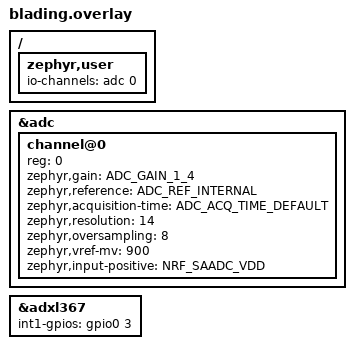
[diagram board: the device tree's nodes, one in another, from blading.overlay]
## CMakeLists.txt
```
# SPDX-License-Identifier: Apache-2.0
cmake_minimum_required(VERSION 3.20.0)

# App devicetree additions (ADC, ADXL367 INT1). The board overlay in boards/
# (flash layout) is still picked up automatically.
list(APPEND EXTRA_DTC_OVERLAY_FILE ${CMAKE_CURRENT_LIST_DIR}/blading.overlay)

find_package(Zephyr REQUIRED HINTS $ENV{ZEPHYR_BASE})
project(blading_tag)

target_sources(app PRIVATE
  src/main.c
  src/app.c
  src/ble.c
  src/proto.c
  src/samplebuf.c
  src/imu.c
  src/motion.c
  src/battery.c
  src/led.c
)
target_sources_ifdef(CONFIG_BLADING_TEST_HOOKS app PRIVATE src/testhook.c)
```

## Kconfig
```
mainmenu "blading-tag"

menu "blading-tag"

config BLADING_BUFFER_SAMPLES
	int "Samples buffered on the tag"
	default 14336
	help
	  Samples the tag can hold while the link is down or too slow
	  (reported as buffer_capacity in Info). 12 bytes each; 14336 is
	  72 s at 200 Hz and takes 168 KB of the 256 KB RAM.

config BLADING_LINK_LOSS_STOP_S
	int "Stop recording after this long without a connection (s)"
	default 300

config BLADING_IDLE_SLEEP_S
	int "Go to System OFF after this long idle (s), 0 = never"
	default 600
	help
	  Idle means READY, not connected and no motion. Only applies when the
	  ADXL367 works and can be armed as a wake-up source, since motion is
	  what wakes the tag again.

config BLADING_MOTION_THRESHOLD_MG
	int "Wake-on-motion threshold (mg)"
	default 150
	range 10 2000

config BLADING_LOW_BATTERY_MV
	int "Status LOW_BATTERY below this voltage (mV)"
	default 2500

config BLADING_TEST_HOOKS
	bool "Hooks for the hardware tests (test builds only)"
	help
	  A RAM mailbox that a J-Link writes commands into, e.g. "short
	  button press", for host/tests/hw. Polls every 20 ms, so it costs
	  power: only for test builds (make build-test, test.conf).

endmenu

source "Kconfig.zephyr"
```

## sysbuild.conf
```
# MCUboot + app. The factory bootloader on the Tag is MCUboot in
# swap-using-move mode with NCS's default nRF54L15 layout (MCUboot 62 KiB,
# slot0 at 0x10000), so we build the same thing.
SB_CONFIG_BOOTLOADER_MCUBOOT=y
SB_CONFIG_MCUBOOT_MODE_SWAP_USING_MOVE=y
```

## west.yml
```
# West manifest for the blading-tag firmware.
#
# The workspace topdir is the repo root (`west init -l firmware`), so
# zephyr/, nrf/, modules/, bootloader/, ... are cloned next to firmware/ and
# are gitignored. See firmware/README.md.
manifest:
  remotes:
    - name: ncs
      url-base: https://github.com/nrfconnect
  projects:
    - name: nrf
      remote: ncs
      repo-path: sdk-nrf
      revision: v3.4.0
      import: true
  self:
    path: firmware
```

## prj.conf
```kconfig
# --- Bluetooth -------------------------------------------------------------
CONFIG_BT=y
CONFIG_BT_PERIPHERAL=y
CONFIG_BT_MAX_CONN=1
CONFIG_BT_DEVICE_NAME="BladeTag"
CONFIG_BT_DEVICE_NAME_DYNAMIC=y
CONFIG_BT_DEVICE_NAME_MAX=16

CONFIG_BT_DIS=y
CONFIG_BT_DIS_MODEL_NUMBER_STR="nRF54L15 Tag"
CONFIG_BT_DIS_FW_REV=y

# ATT MTU 247 and full-size LL packets: one Data notification = 19 samples.
CONFIG_BT_L2CAP_TX_MTU=247
CONFIG_BT_BUF_ACL_TX_SIZE=251
CONFIG_BT_BUF_ACL_RX_SIZE=251
CONFIG_BT_CTLR_DATA_LENGTH_MAX=251

# Connection parameters from PROTOCOL.md 1.2: 30-50 ms, latency 0, 4 s
# supervision timeout, 2M PHY.
CONFIG_BT_GAP_AUTO_UPDATE_CONN_PARAMS=y
CONFIG_BT_PERIPHERAL_PREF_MIN_INT=24
CONFIG_BT_PERIPHERAL_PREF_MAX_INT=40
CONFIG_BT_PERIPHERAL_PREF_LATENCY=0
CONFIG_BT_PERIPHERAL_PREF_TIMEOUT=400
CONFIG_BT_AUTO_PHY_PERIPHERAL_2M=y
# Highest TX power the tag's QFN48 nRF54L15 supports (+8 dBm is CSP only).
# Costs ~+60 uA while recording and ~+5 uA while advertising in READY; worth
# it for an ankle tag talking to a phone on the body. See PLAN.md.
CONFIG_BT_CTLR_TX_PWR_PLUS_7=y

# Control writes run in the BT RX thread and save settings / talk to the IMU.
CONFIG_BT_RX_STACK_SIZE=3072

# --- Firmware updates over BLE (MCUboot + mcumgr SMP) -----------------------
CONFIG_NCS_SAMPLE_MCUMGR_BT_OTA_DFU=y
# A crash resets instead of halting, so MCUboot can revert an unconfirmed image.
CONFIG_RESET_ON_FATAL_ERROR=y

# --- Sensors ---------------------------------------------------------------
CONFIG_GPIO=y
CONFIG_SPI=y
CONFIG_I2C=y
CONFIG_SENSOR=y
# The BMI270 driver does the chip init; src/imu.c runs the FIFO itself.
CONFIG_BMI270=y
CONFIG_BMI270_TRIGGER_NONE=y
# src/motion.c drives the ADXL367 directly. BME688 is unused.
CONFIG_ADXL367=n
CONFIG_BME680=n
CONFIG_ADC=y

# --- Persistence (session_id, position) -------------------------------------
CONFIG_FLASH=y
CONFIG_FLASH_MAP=y
CONFIG_ZMS=y
CONFIG_SETTINGS=y
CONFIG_SETTINGS_ZMS=y

# --- Power -------------------------------------------------------------------
CONFIG_POWEROFF=y

CONFIG_SYSTEM_WORKQUEUE_STACK_SIZE=3072

# Logging over RTT (J-Link). The Tag has no UART connector.
CONFIG_LOG=y
CONFIG_USE_SEGGER_RTT=y
CONFIG_LOG_BACKEND_RTT=y
CONFIG_LOG_BACKEND_UART=n
CONFIG_UART_CONSOLE=n
CONFIG_RTT_CONSOLE=y
# MCUboot's boot log alone nearly fills the default 1 KB.
CONFIG_SEGGER_RTT_BUFFER_SIZE_UP=4096
```

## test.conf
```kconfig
# Test build for the hardware tests in host/tests/hw (make build-test).
# Applied on top of prj.conf. Don't ship it: it polls a RAM mailbox.
CONFIG_BLADING_TEST_HOOKS=y
# The tag sits still in the DK header between test runs, and the J-Link can't
# wake it from System OFF.
CONFIG_BLADING_IDLE_SLEEP_S=0
```

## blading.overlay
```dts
/*
 * App devicetree additions, on top of boards/nrf54l15tag_nrf54l15_cpuapp.overlay
 * (the flash layout, owned by the OTA setup). Added via EXTRA_DTC_OVERLAY_FILE.
 */
#include <zephyr/dt-bindings/adc/adc.h>
#include <zephyr/dt-bindings/adc/nrf-saadc.h>

/ {
	zephyr,user {
		io-channels = <&adc 0>;
	};
};

/* Coin-cell voltage: VDD, gain 1/4 against the 0.9 V reference = 3.6 V full scale. */
&adc {
	#address-cells = <1>;
	#size-cells = <0>;
	status = "okay";

	channel@0 {
		reg = <0>;
		zephyr,gain = "ADC_GAIN_1_4";
		zephyr,reference = "ADC_REF_INTERNAL";
		zephyr,acquisition-time = <ADC_ACQ_TIME_DEFAULT>;
		zephyr,resolution = <14>;
		zephyr,oversampling = <8>;
		zephyr,vref-mv = <900>;
		zephyr,input-positive = <NRF_SAADC_VDD>;
	};
};

/*
 * ADXL367 INT1 is on P0.03 (as in sdk-nrf's fast_pair/locator_tag overlay for
 * this board). Port 0 supports SENSE, so it can wake from System OFF.
 */
&adxl367 {
	int1-gpios = <&gpio0 3 GPIO_ACTIVE_HIGH>;
};
```

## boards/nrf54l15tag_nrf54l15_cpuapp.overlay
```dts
/*
 * Flash layout of the factory-programmed nRF54L15 Tag.
 *
 * The factory MCUboot uses NCS's "FLPR" partition variant
 * (WITH_FLPR_PARTITIONS in nrf54l15_cpuapp_partition.dtsi), not the default
 * one. Read back from a stock tag over SWD:
 *
 *   mcuboot  0x000000  62 KiB
 *   slot0    0x010000  664 KiB  (image trailer at the end, 0x0b6000)
 *   slot1    0x0b6000  664 KiB
 *   storage  0x15c000  36 KiB
 *
 * The app has to agree with the bootloader on these, or it writes its
 * "confirmed" flag to the wrong place and MCUboot reverts the update. Keep
 * this in sync with sysbuild/mcuboot.overlay (which includes this file).
 */

/delete-node/ &slot1_partition;
/delete-node/ &storage_partition;

&cpuapp_rram {
	partitions {
		slot0_partition: partition@10000 {
			compatible = "zephyr,mapped-partition";
			label = "image-0";
			reg = <0x10000 DT_SIZE_K(664)>;
		};

		slot1_partition: partition@b6000 {
			compatible = "zephyr,mapped-partition";
			label = "image-1";
			reg = <0xb6000 DT_SIZE_K(664)>;
		};

		storage_partition: partition@15c000 {
			compatible = "zephyr,mapped-partition";
			label = "storage";
			reg = <0x15c000 DT_SIZE_K(36)>;
		};
	};
};
```

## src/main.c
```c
/*
 * blading-tag firmware for the nRF54L15 Tag.
 *
 * Streams BMI270 accelerometer + gyroscope data over BLE when the app asks
 * for it (PROTOCOL.md), sleeps in System OFF when idle, and takes firmware
 * updates over BLE (MCUboot + mcumgr SMP). See app.c for the state machine.
 */
#include <app_version.h>
#include <zephyr/bluetooth/bluetooth.h>
#include <zephyr/dfu/mcuboot.h>
#include <zephyr/kernel.h>
#include <zephyr/logging/log.h>

#include "app.h"
#include "ble.h"

LOG_MODULE_REGISTER(main, LOG_LEVEL_INF);

int main(void)
{
	int err;

	LOG_INF("blading-tag %s", APP_VERSION_EXTENDED_STRING);

	app_init();

	err = bt_enable(NULL);
	if (err) {
		LOG_ERR("bt_enable failed: %d", err);
		return 0;
	}

	ble_init();

	/*
	 * Bluetooth (and with it SMP) is up, so a further update is possible:
	 * keep this image. If we never get here, MCUboot reverts it on reset.
	 */
	if (!boot_is_img_confirmed()) {
		err = boot_write_img_confirmed();
		LOG_INF("image confirmed: %d", err);
	}

	app_run();
	return 0;
}
```

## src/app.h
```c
/*
 * Tag state machine (PROTOCOL.md 1.4-1.9): READY / RECORDING, the sample
 * buffer and Data packets, link loss, persistence, button, sleep.
 */
#ifndef BLADING_APP_H_
#define BLADING_APP_H_

#include <stdbool.h>
#include <stddef.h>
#include <stdint.h>

#include "proto.h"

/* Before bt_enable(): settings, LED, sensors, button. */
int app_init(void);
/* After Bluetooth is up: periodic work, advertising. */
void app_run(void);

/* Called by ble.c. */
void app_encode_info(uint8_t out[PROTO_INFO_LEN]);
void app_encode_status(uint8_t out[PROTO_STATUS_LEN]);
/* Returns 0 or a PROTO_ERR_* code. */
int app_control(const uint8_t *buf, size_t len);
void app_on_connected(void);
void app_on_disconnected(void);
/* The peer acknowledged the Data packet sent with this token. */
void app_on_data_acked(uint32_t token);
/* Wake the TX thread (new data, notifications enabled, TX done). */
void app_kick(void);
void app_adv_fields(uint8_t *state, uint8_t *position, uint16_t *battery_mv, bool *fast);

/* What a short button press does: start (defaults) while idle, otherwise ignore. Also
 * used by testhook.c. Call from the system workqueue. */
void app_button_short(void);
/* Release after a press begun in was_recording; held means the 2 s threshold passed. */
void app_button_release(bool was_recording, bool held);

#endif /* BLADING_APP_H_ */
```

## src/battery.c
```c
/*
 * Coin-cell voltage. The Tag runs straight off the CR2032, so VDD is the
 * battery voltage. Measured with the SAADC's internal VDD input (see
 * blading.overlay: gain 1/4, 0.9 V reference, so 3.6 V full scale).
 */
#include "battery.h"

#include <zephyr/drivers/adc.h>
#include <zephyr/kernel.h>
#include <zephyr/logging/log.h>

LOG_MODULE_REGISTER(battery, LOG_LEVEL_INF);

static const struct adc_dt_spec vdd = ADC_DT_SPEC_GET(DT_PATH(zephyr_user));
static atomic_t last_mv;
static bool ready;

int battery_init(void)
{
	if (!adc_is_ready_dt(&vdd)) {
		return -ENODEV;
	}
	int err = adc_channel_setup_dt(&vdd);

	if (err) {
		LOG_ERR("ADC setup failed: %d", err);
		return err;
	}
	ready = true;
	return battery_measure();
}

int battery_measure(void)
{
	int16_t raw;
	struct adc_sequence seq = {
		.buffer = &raw,
		.buffer_size = sizeof(raw),
	};
	int32_t mv;
	int err;

	if (!ready) {
		return -ENODEV;
	}

	adc_sequence_init_dt(&vdd, &seq);
	err = adc_read_dt(&vdd, &seq);
	if (err) {
		return err;
	}

	mv = raw;
	err = adc_raw_to_millivolts_dt(&vdd, &mv);
	if (err) {
		return err;
	}

	atomic_set(&last_mv, CLAMP(mv, 0, UINT16_MAX));
	return 0;
}

uint16_t battery_mv(void)
{
	return (uint16_t)atomic_get(&last_mv);
}
```

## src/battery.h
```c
#ifndef BLADING_BATTERY_H_
#define BLADING_BATTERY_H_

#include <stdint.h>

int battery_init(void);
/* Take a new reading. */
int battery_measure(void);
/* Last reading in mV, 0 if none. */
uint16_t battery_mv(void);

#endif /* BLADING_BATTERY_H_ */
```

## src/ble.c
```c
#include "ble.h"

#include <stdio.h>
#include <string.h>
#include <zephyr/bluetooth/bluetooth.h>
#include <zephyr/bluetooth/conn.h>
#include <zephyr/bluetooth/gatt.h>
#include <zephyr/bluetooth/hci.h>
#include <zephyr/bluetooth/uuid.h>
#include <zephyr/logging/log.h>

#include "app.h"
#include "proto.h"

LOG_MODULE_REGISTER(ble, LOG_LEVEL_INF);

#define BLADING_UUID(short16)                                                                      \
	BT_UUID_128_ENCODE(PROTO_UUID_W32(short16), PROTO_UUID_W1, PROTO_UUID_W2, PROTO_UUID_W3,   \
			   PROTO_UUID_W48)

static const struct bt_uuid_128 svc_uuid = BT_UUID_INIT_128(BLADING_UUID(0x0001));
static const struct bt_uuid_128 info_uuid = BT_UUID_INIT_128(BLADING_UUID(0x0002));
static const struct bt_uuid_128 control_uuid = BT_UUID_INIT_128(BLADING_UUID(0x0003));
static const struct bt_uuid_128 status_uuid = BT_UUID_INIT_128(BLADING_UUID(0x0004));
static const struct bt_uuid_128 data_uuid = BT_UUID_INIT_128(BLADING_UUID(0x0005));

/* Notifications in flight at once; matches CONFIG_BT_CONN_TX_MAX. */
#define TX_CREDITS 3

static K_SEM_DEFINE(tx_credits, 0, TX_CREDITS);
static struct k_spinlock conn_lock;
static struct bt_conn *cur_conn;
/* Bumped on every connect/disconnect, so stale completions are ignored. */
static atomic_t conn_gen;
static atomic_t shutting_down;

static char name[sizeof("BladeTag-XXXX")];
static uint8_t mfg[PROTO_ADV_MFG_LEN];

static ssize_t read_info(struct bt_conn *conn, const struct bt_gatt_attr *attr, void *buf,
			 uint16_t len, uint16_t offset)
{
	uint8_t v[PROTO_INFO_LEN];

	app_encode_info(v);
	return bt_gatt_attr_read(conn, attr, buf, len, offset, v, sizeof(v));
}

static ssize_t read_status(struct bt_conn *conn, const struct bt_gatt_attr *attr, void *buf,
			   uint16_t len, uint16_t offset)
{
	uint8_t v[PROTO_STATUS_LEN];

	app_encode_status(v);
	return bt_gatt_attr_read(conn, attr, buf, len, offset, v, sizeof(v));
}

static ssize_t write_control(struct bt_conn *conn, const struct bt_gatt_attr *attr,
			     const void *buf, uint16_t len, uint16_t offset, uint8_t flags)
{
	if (offset != 0) {
		return BT_GATT_ERR(BT_ATT_ERR_INVALID_OFFSET);
	}

	int err = app_control(buf, len);

	return err ? BT_GATT_ERR(err) : len;
}

static void ccc_changed(const struct bt_gatt_attr *attr, uint16_t value)
{
	app_kick();
}

BT_GATT_SERVICE_DEFINE(blading_svc,
	BT_GATT_PRIMARY_SERVICE(&svc_uuid),
	BT_GATT_CHARACTERISTIC(&info_uuid.uuid, BT_GATT_CHRC_READ, BT_GATT_PERM_READ, read_info,
			       NULL, NULL),
	BT_GATT_CHARACTERISTIC(&control_uuid.uuid, BT_GATT_CHRC_WRITE, BT_GATT_PERM_WRITE, NULL,
			       write_control, NULL),
	BT_GATT_CHARACTERISTIC(&status_uuid.uuid, BT_GATT_CHRC_READ | BT_GATT_CHRC_NOTIFY,
			       BT_GATT_PERM_READ, read_status, NULL, NULL),
	BT_GATT_CCC(ccc_changed, BT_GATT_PERM_READ | BT_GATT_PERM_WRITE),
	BT_GATT_CHARACTERISTIC(&data_uuid.uuid, BT_GATT_CHRC_NOTIFY, BT_GATT_PERM_NONE, NULL, NULL,
			       NULL),
	BT_GATT_CCC(ccc_changed, BT_GATT_PERM_READ | BT_GATT_PERM_WRITE),
);

/* Value attributes, see the attribute list above. */
#define STATUS_ATTR (&blading_svc.attrs[6])
#define DATA_ATTR   (&blading_svc.attrs[9])

static struct bt_conn *conn_get(void)
{
	k_spinlock_key_t key = k_spin_lock(&conn_lock);
	struct bt_conn *conn = cur_conn ? bt_conn_ref(cur_conn) : NULL;

	k_spin_unlock(&conn_lock, key);
	return conn;
}

bool ble_connected(void)
{
	struct bt_conn *conn = conn_get();

	if (conn) {
		bt_conn_unref(conn);
	}
	return conn != NULL;
}

uint16_t ble_mtu(void)
{
	struct bt_conn *conn = conn_get();
	uint16_t mtu = 0;

	if (conn) {
		mtu = bt_gatt_get_mtu(conn);
		bt_conn_unref(conn);
	}
	return mtu;
}

bool ble_data_subscribed(void)
{
	struct bt_conn *conn = conn_get();
	bool on = false;

	if (conn) {
		on = bt_gatt_is_subscribed(conn, DATA_ATTR, BT_GATT_CCC_NOTIFY);
		bt_conn_unref(conn);
	}
	return on;
}

/*
 * A notification's user_data: the connection generation it was sent on
 * (low 8 bits) and, for Data, the caller's token (upper 24 bits).
 */
#define UD_MAKE(gen, token) ((void *)(uintptr_t)(((uint32_t)(token) << 8) | ((gen) & 0xff)))
#define UD_GEN(ud)          ((uint32_t)(uintptr_t)(ud) & 0xff)
#define UD_TOKEN(ud)        ((uint32_t)(uintptr_t)(ud) >> 8)

static bool same_conn_gen(void *user_data)
{
	return UD_GEN(user_data) == ((uint32_t)atomic_get(&conn_gen) & 0xff);
}

static void notify_done(struct bt_conn *conn, void *user_data)
{
	if (same_conn_gen(user_data)) {
		k_sem_give(&tx_credits);
	}
	app_kick();
}

/*
 * Zephyr calls this once the controller reports the packet complete:
 * acknowledged by the peer's link layer, or flushed at a link loss (app.c
 * keeps a few packets for that). It also calls it for packets the host
 * throws away at a disconnect: process_unack_tx() destroys them after the
 * connection is already in DISCONNECT_COMPLETE, and ATT runs the callback
 * from a work item that can come before our disconnected() callback. So only
 * a callback while still connected, on the same connection, is passed on.
 * Getting it wrong the other way only sends a packet twice.
 */
static void data_done(struct bt_conn *conn, void *user_data)
{
	struct bt_conn_info info;
	bool acked = same_conn_gen(user_data) && bt_conn_get_info(conn, &info) == 0 &&
		     info.state == BT_CONN_STATE_CONNECTED;

	if (same_conn_gen(user_data)) {
		k_sem_give(&tx_credits);
	}
	if (acked) {
		app_on_data_acked(UD_TOKEN(user_data));
	}
	app_kick();
}

static int notify(const struct bt_gatt_attr *attr, const uint8_t *buf, size_t len,
		  k_timeout_t timeout, bt_gatt_complete_func_t done, uint32_t token)
{
	struct bt_conn *conn = conn_get();
	int err;

	if (!conn) {
		return -ENOTCONN;
	}
	if (!bt_gatt_is_subscribed(conn, attr, BT_GATT_CCC_NOTIFY)) {
		bt_conn_unref(conn);
		return -EACCES;
	}

	uint32_t gen = (uint32_t)atomic_get(&conn_gen);

	if (k_sem_take(&tx_credits, timeout) != 0) {
		bt_conn_unref(conn);
		return -EAGAIN;
	}

	struct bt_gatt_notify_params params = {
		.attr = attr,
		.data = buf,
		.len = len,
		.func = done,
		.user_data = UD_MAKE(gen, token),
	};

	err = bt_gatt_notify_cb(conn, &params);
	if (err) {
		k_sem_give(&tx_credits);
		err = err == -ENOTCONN ? -ENOTCONN : -EAGAIN;
	}
	bt_conn_unref(conn);
	return err;
}

int ble_notify_status(const uint8_t *buf, size_t len, k_timeout_t timeout)
{
	return notify(STATUS_ATTR, buf, len, timeout, notify_done, 0);
}

int ble_notify_data(const uint8_t *buf, size_t len, k_timeout_t timeout, uint32_t token)
{
	return notify(DATA_ATTR, buf, len, timeout, data_done, token);
}

/* --- Advertising ---------------------------------------------------------- */

static struct bt_data ad[] = {
	BT_DATA_BYTES(BT_DATA_FLAGS, BT_LE_AD_GENERAL | BT_LE_AD_NO_BREDR),
	BT_DATA_BYTES(BT_DATA_UUID128_ALL, BLADING_UUID(0x0001)),
	BT_DATA(BT_DATA_MANUFACTURER_DATA, mfg, sizeof(mfg)),
};

static struct bt_data sd[] = {
	BT_DATA(BT_DATA_NAME_COMPLETE, name, 0),
};

/*
 * ~1 s when idle. While recording without a link, advertise faster so the
 * phone reconnects before the buffer fills.
 */
static const struct bt_le_adv_param adv_slow =
	BT_LE_ADV_PARAM_INIT(BT_LE_ADV_OPT_CONN, 1600, 1760, NULL); /* 1.0-1.1 s */
static const struct bt_le_adv_param adv_fast =
	BT_LE_ADV_PARAM_INIT(BT_LE_ADV_OPT_CONN, 160, 240, NULL); /* 100-150 ms */

/* Whether we started advertising, and with which interval. Cleared on connect. */
static atomic_t adv_on;
static bool adv_on_fast;

/*
 * Runs on the system workqueue only. Stopping connectable advertising frees
 * its pending connection object, which calls recycled() -> ble_adv_refresh()
 * again. So only stop when the interval changes; otherwise update the data in
 * place, or this loops forever.
 */
static void adv_work_fn(struct k_work *work)
{
	uint8_t state, position;
	uint16_t battery;
	bool fast;
	int err;

	if (atomic_get(&shutting_down) || ble_connected()) {
		return;
	}

	app_adv_fields(&state, &position, &battery, &fast);
	proto_encode_adv_mfg(mfg, state, position, battery);

	if (atomic_get(&adv_on)) {
		if (fast == adv_on_fast &&
		    bt_le_adv_update_data(ad, ARRAY_SIZE(ad), sd, ARRAY_SIZE(sd)) == 0) {
			return;
		}
		bt_le_adv_stop();
		atomic_set(&adv_on, 0);
	}

	err = bt_le_adv_start(fast ? &adv_fast : &adv_slow, ad, ARRAY_SIZE(ad), sd,
			      ARRAY_SIZE(sd));
	if (err == 0) {
		atomic_set(&adv_on, 1);
		adv_on_fast = fast;
		LOG_INF("advertising (%s)", fast ? "fast" : "slow");
	} else if (err == -ENOMEM) {
		/* The old connection object isn't recycled yet; recycled() retries. */
		LOG_DBG("adv start: %d", err);
	} else {
		LOG_WRN("adv start failed: %d", err);
	}
}

static K_WORK_DEFINE(adv_work, adv_work_fn);

void ble_adv_refresh(void)
{
	k_work_submit(&adv_work);
}

/* --- Connections ------------------------------------------------------------ */

static void reset_credits(void)
{
	atomic_inc(&conn_gen);
	k_sem_reset(&tx_credits);
	for (int i = 0; i < TX_CREDITS; i++) {
		k_sem_give(&tx_credits);
	}
}

static void connected(struct bt_conn *conn, uint8_t err)
{
	if (err) {
		LOG_WRN("connection failed: 0x%02x", err);
		return;
	}

	k_spinlock_key_t key = k_spin_lock(&conn_lock);

	if (cur_conn) {
		k_spin_unlock(&conn_lock, key);
		return;
	}
	cur_conn = bt_conn_ref(conn);
	k_spin_unlock(&conn_lock, key);

	/* The controller stops advertising when a connection is made. */
	atomic_set(&adv_on, 0);
	reset_credits();
	LOG_INF("connected");
	app_on_connected();
}

static void disconnected(struct bt_conn *conn, uint8_t reason)
{
	k_spinlock_key_t key = k_spin_lock(&conn_lock);

	if (conn != cur_conn) {
		k_spin_unlock(&conn_lock, key);
		return;
	}
	cur_conn = NULL;
	k_spin_unlock(&conn_lock, key);
	bt_conn_unref(conn);

	reset_credits();
	LOG_INF("disconnected (0x%02x)", reason);
	app_on_disconnected();
}

/* The connection object is free again: advertising can restart. */
static void recycled(void)
{
	ble_adv_refresh();
}

BT_CONN_CB_DEFINE(conn_cb) = {
	.connected = connected,
	.disconnected = disconnected,
	.recycled = recycled,
};

int ble_init(void)
{
	bt_addr_le_t addrs[1];
	size_t count = 1;

	bt_id_get(addrs, &count);
	snprintf(name, sizeof(name), "BladeTag-%02X%02X", addrs[0].a.val[1], addrs[0].a.val[0]);
	sd[0].data_len = strlen(name);
	bt_set_name(name);

	reset_credits();
	ble_adv_refresh();
	LOG_INF("name %s", name);
	return 0;
}

void ble_shutdown(void)
{
	atomic_set(&shutting_down, 1);

	struct bt_conn *conn = conn_get();

	if (conn) {
		bt_conn_disconnect(conn, BT_HCI_ERR_REMOTE_USER_TERM_CONN);
		bt_conn_unref(conn);
		for (int i = 0; i < 20 && ble_connected(); i++) {
			k_msleep(50);
		}
	}
	bt_le_adv_stop();
	atomic_set(&adv_on, 0);
}
```

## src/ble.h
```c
/*
 * Bluetooth side of the protocol: advertising, the Blading GATT service and
 * notification flow control. The protocol state lives in app.c.
 */
#ifndef BLADING_BLE_H_
#define BLADING_BLE_H_

#include <stdbool.h>
#include <stddef.h>
#include <stdint.h>
#include <zephyr/kernel.h>

/* Call after bt_enable(). Sets the name and starts advertising. */
int ble_init(void);

/* Re-read the advertised state (state, position, battery) and restart. */
void ble_adv_refresh(void);

bool ble_connected(void);
/* ATT MTU of the current connection, 0 if none. */
uint16_t ble_mtu(void);
bool ble_data_subscribed(void);

/*
 * Notify Status / Data. At most a few notifications are in flight at once;
 * these wait up to `timeout` for one to complete.
 * Returns 0, -ENOTCONN, -EACCES (not subscribed) or -EAGAIN (timed out).
 *
 * Once the controller reports a Data notification complete, ble.c calls
 * app_on_data_acked(token), in order. That usually means the peer
 * acknowledged it, but right before a link loss it can also mean it was
 * flushed. It isn't called for packets the host drops at a disconnect.
 * token has 24 bits.
 */
int ble_notify_status(const uint8_t *buf, size_t len, k_timeout_t timeout);
int ble_notify_data(const uint8_t *buf, size_t len, k_timeout_t timeout, uint32_t token);

/* Disconnect, stop advertising and keep it stopped (before System OFF). */
void ble_shutdown(void);

#endif /* BLADING_BLE_H_ */
```

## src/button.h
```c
#ifndef BLADING_BUTTON_H_
#define BLADING_BUTTON_H_

#include <stdbool.h>

enum button_action { BUTTON_NONE, BUTTON_START, BUTTON_STOP, BUTTON_SLEEP };

/* Ignore presses spanning a phone-driven state change: never stop a newly
 * started recording or restart one that ended while the button was down. */
static inline enum button_action button_action(bool was_recording, bool recording, bool held)
{
	if (was_recording != recording) {
		return BUTTON_NONE;
	}
	if (recording) {
		return held ? BUTTON_STOP : BUTTON_NONE;
	}
	return held ? BUTTON_SLEEP : BUTTON_START;
}

#endif
```

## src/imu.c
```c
/*
 * BMI270 FIFO reader.
 *
 * Zephyr's BMI270 driver does the chip init and the config-file upload at
 * boot. It only offers per-sample data-ready triggers, which can miss samples
 * without noticing and wake the CPU at the full sample rate. So once the chip
 * is up, this module drives the FIFO through the driver's register accessors:
 *
 * - Headerless FIFO with accel + gyro: fixed 12-byte frames, gyro then accel.
 * - The watermark interrupt (INT1, P1.04) fires every ~100 ms. Its edge is
 *   timestamped in the ISR and belongs to the W-th frame in the FIFO, which
 *   gives each batch's start time without per-sample interrupts.
 * - A poll timeout backs up the interrupt, and a full FIFO (overflow) is
 *   detected and the lost samples are counted, so sample_index stays exact.
 */
#include "imu.h"

#include <string.h>
#include <zephyr/device.h>
#include <zephyr/drivers/gpio.h>
#include <zephyr/kernel.h>
#include <zephyr/logging/log.h>
#include <zephyr/sys/byteorder.h>

LOG_MODULE_REGISTER(imu, LOG_LEVEL_INF);

/*
 * Exported by Zephyr's BMI270 driver (drivers/sensor/bosch/bmi270/bmi270.h,
 * which is private to the driver, so the prototypes are repeated here).
 */
int bmi270_reg_read(const struct device *dev, uint8_t reg, uint8_t *data, uint16_t length);
int bmi270_reg_write(const struct device *dev, uint8_t reg, const uint8_t *data, uint16_t length);

#define REG_CHIP_ID       0x00
#define REG_ERR           0x02
#define REG_FIFO_LENGTH_0 0x24
#define REG_FIFO_DATA     0x26
#define REG_ACC_CONF      0x40
#define REG_ACC_RANGE     0x41
#define REG_GYR_CONF      0x42
#define REG_GYR_RANGE     0x43
#define REG_FIFO_DOWNS    0x45
#define REG_FIFO_WTM_0    0x46
#define REG_FIFO_CONFIG_0 0x48
#define REG_FIFO_CONFIG_1 0x49
#define REG_INT1_IO_CTRL  0x53
#define REG_INT_LATCH     0x55
#define REG_INT_MAP_DATA  0x58
#define REG_PWR_CONF      0x7C
#define REG_PWR_CTRL      0x7D
#define REG_CMD           0x7E

#define CHIP_ID 0x24

#define ACC_CONF_BWP_NORM_AVG4 (0x2 << 4)
#define ACC_CONF_FILTER_PERF   BIT(7)
#define GYR_CONF_BWP_NORM      (0x2 << 4)
#define GYR_CONF_NOISE_PERF    BIT(6)
#define GYR_CONF_FILTER_PERF   BIT(7)
#define FIFO_DOWNS_FILTERED    0x88 /* filtered data, no downsampling (reset value) */
#define FIFO_CONFIG_1_ACC_GYR  (BIT(6) | BIT(7)) /* header_en (bit 4) cleared */
#define INT_IO_OUTPUT_EN       BIT(3)
#define INT_IO_ACTIVE_HIGH     BIT(1)
#define INT_MAP_FWM_INT1       BIT(1)
#define PWR_CONF_APS           BIT(0)
#define PWR_CONF_FIFO_SELF_WKUP BIT(1)
#define PWR_CTRL_GYR           BIT(1)
#define PWR_CTRL_ACC           BIT(2)
#define CMD_FIFO_FLUSH         0xB0

#define FIFO_BYTES  2048
#define FRAME_BYTES 12
#define MAX_FRAMES  (FIFO_BYTES / FRAME_BYTES)

/* Gyro start-up from suspend is 45 ms; these samples are discarded. */
#define STARTUP_MS 55

static const struct device *const dev = DEVICE_DT_GET(DT_NODELABEL(bmi270));
static const struct gpio_dt_spec int1 = GPIO_DT_SPEC_GET(DT_NODELABEL(bmi270), irq_gpios);
static struct gpio_callback int1_cb;

static imu_batch_cb_t batch_cb;
static bool present;

static K_SEM_DEFINE(wake_sem, 0, 1);
static K_SEM_DEFINE(stopped_sem, 0, 1);
static atomic_t running;
static atomic_t stop_req;

static struct k_spinlock irq_lock;
static bool irq_pending;
static uint64_t irq_t_us;

/* Owned by the IMU thread while running, by imu_start() otherwise. */
static struct {
	uint16_t odr_hz;
	uint32_t wtm_frames;
	uint32_t nominal_ns;
	uint32_t period_ns;
	uint32_t next_index;
	bool have_last;
	uint32_t last_index;
	uint64_t last_t_us;
	bool have_ref;
	uint32_t ref_index;
	uint64_t ref_t_us;
} st;

static atomic_t period_ns_shared = ATOMIC_INIT(5000000);

static uint8_t fifo_buf[MAX_FRAMES * FRAME_BYTES];
static struct imu6 samples[MAX_FRAMES];

uint64_t tag_time_us(void)
{
	return k_cyc_to_us_floor64(k_cycle_get_64());
}

uint32_t imu_period_ns(void)
{
	return (uint32_t)atomic_get(&period_ns_shared);
}

static int wr(uint8_t reg, uint8_t val)
{
	int err = bmi270_reg_write(dev, reg, &val, 1);

	/* 2 us between writes in normal mode; be generous. */
	k_busy_wait(5);
	return err;
}

static void int1_isr(const struct device *port, struct gpio_callback *cb, uint32_t pins)
{
	k_spinlock_key_t key = k_spin_lock(&irq_lock);

	irq_t_us = tag_time_us();
	irq_pending = true;
	k_spin_unlock(&irq_lock, key);
	k_sem_give(&wake_sem);
}

static uint8_t odr_bits(uint16_t hz)
{
	switch (hz) {
	case 25:
		return 0x06;
	case 50:
		return 0x07;
	case 100:
		return 0x08;
	case 200:
		return 0x09;
	case 400:
		return 0x0A;
	default:
		return 0x0B; /* 800 */
	}
}

static uint8_t acc_range_bits(uint8_t g)
{
	switch (g) {
	case 2:
		return 0;
	case 4:
		return 1;
	case 8:
		return 2;
	default:
		return 3; /* 16 g */
	}
}

static uint8_t gyr_range_bits(uint16_t dps)
{
	switch (dps) {
	case 125:
		return 4;
	case 250:
		return 3;
	case 500:
		return 2;
	case 1000:
		return 1;
	default:
		return 0; /* 2000 dps */
	}
}

static uint64_t frames_us(uint32_t frames, uint32_t period_ns)
{
	return ((uint64_t)frames * period_ns + 500) / 1000;
}

/* Sensors off, FIFO off, advanced power save on: ~3.5 uA suspend. */
static void power_down(void)
{
	gpio_pin_interrupt_configure_dt(&int1, GPIO_INT_DISABLE);
	wr(REG_INT_MAP_DATA, 0);
	wr(REG_PWR_CTRL, 0);
	wr(REG_FIFO_CONFIG_1, 0);
	wr(REG_CMD, CMD_FIFO_FLUSH);
	wr(REG_PWR_CONF, PWR_CONF_APS | PWR_CONF_FIFO_SELF_WKUP);
}

static void read_fifo(bool final)
{
	uint8_t lenb[2];
	bool irq;
	uint64_t t_irq;

	/*
	 * Take the IRQ flag before reading the fill level, so a watermark
	 * edge we count is always for a frame this read includes.
	 */
	k_spinlock_key_t key = k_spin_lock(&irq_lock);

	irq = irq_pending;
	t_irq = irq_t_us;
	irq_pending = false;
	k_spin_unlock(&irq_lock, key);

	if (bmi270_reg_read(dev, REG_FIFO_LENGTH_0, lenb, 2) != 0) {
		LOG_WRN("FIFO length read failed");
		return;
	}

	uint64_t now = tag_time_us();
	uint32_t n = (sys_get_le16(lenb) & 0x3FFF) / FRAME_BYTES;

	if (n == 0) {
		return;
	}

	/* With stop_on_full off, a full FIFO overwrites its oldest frames. */
	bool overflow = n >= MAX_FRAMES - 1;

	n = MIN(n, MAX_FRAMES);

	if (bmi270_reg_read(dev, REG_FIFO_DATA, fifo_buf, n * FRAME_BYTES) != 0) {
		LOG_WRN("FIFO data read failed");
		return;
	}

	for (uint32_t i = 0; i < n; i++) {
		const uint8_t *f = &fifo_buf[i * FRAME_BYTES];

		samples[i].gx = (int16_t)sys_get_le16(&f[0]);
		samples[i].gy = (int16_t)sys_get_le16(&f[2]);
		samples[i].gz = (int16_t)sys_get_le16(&f[4]);
		samples[i].ax = (int16_t)sys_get_le16(&f[6]);
		samples[i].ay = (int16_t)sys_get_le16(&f[8]);
		samples[i].az = (int16_t)sys_get_le16(&f[10]);
	}

	uint32_t p = st.period_ns;
	uint64_t predicted = 0;
	uint64_t t_first;
	uint32_t lost = 0;
	bool timed = false;

	if (st.have_last) {
		predicted = st.last_t_us + frames_us(st.next_index - st.last_index, p);
	}

	if (overflow) {
		/* The newest frame was taken about now. */
		t_first = now - frames_us(n - 1, p);
		if (st.have_last && t_first > predicted) {
			lost = (uint32_t)(((t_first - predicted) * 1000 + p / 2) / p);
		}
		LOG_WRN("FIFO overflow, ~%u samples lost", lost);
	} else if (irq && n >= st.wtm_frames && !final) {
		/* The watermark edge is the W-th frame in the FIFO. */
		t_first = t_irq - frames_us(st.wtm_frames - 1, p);
		timed = true;
		if (st.have_last) {
			int64_t err_us = (int64_t)(t_first - predicted);

			/* An edge that doesn't fit is from a race; ignore it. */
			if (err_us > (int64_t)frames_us(3, p) || err_us < -(int64_t)frames_us(3, p)) {
				t_first = predicted;
				timed = false;
			}
		}
	} else if (st.have_last) {
		t_first = predicted;
	} else {
		t_first = now - frames_us(n - 1, p);
	}

	uint32_t index = st.next_index + lost;

	batch_cb(samples, n, index, t_first, lost);

	st.next_index = index + n;
	st.last_index = index;
	st.last_t_us = t_first;
	st.have_last = true;

	/* Fit the true sample period from IRQ-timed batches. */
	if (timed) {
		if (!st.have_ref) {
			st.have_ref = true;
			st.ref_index = index;
			st.ref_t_us = t_first;
		} else if (index - st.ref_index >= 2u * st.odr_hz) {
			uint64_t est = ((t_first - st.ref_t_us) * 1000) / (index - st.ref_index);
			uint32_t lo = st.nominal_ns - st.nominal_ns / 20;
			uint32_t hi = st.nominal_ns + st.nominal_ns / 20;

			st.period_ns = CLAMP(est, lo, hi);
			atomic_set(&period_ns_shared, st.period_ns);
		}
	}
}

static void imu_thread(void *a, void *b, void *c)
{
	for (;;) {
		if (!atomic_get(&running)) {
			k_sem_take(&wake_sem, K_FOREVER);
			continue;
		}

		/* Backstop in case a watermark edge is missed. */
		k_timeout_t poll = K_USEC(frames_us(3 * st.wtm_frames, st.nominal_ns));

		k_sem_take(&wake_sem, poll);

		if (atomic_get(&stop_req)) {
			read_fifo(true);
			power_down();
			atomic_set(&running, 0);
			atomic_set(&stop_req, 0);
			k_sem_give(&stopped_sem);
			continue;
		}

		read_fifo(false);
	}
}

K_THREAD_DEFINE(imu_tid, 2048, imu_thread, NULL, NULL, NULL, 2, 0, 0);

int imu_init(imu_batch_cb_t cb)
{
	uint8_t id = 0;

	batch_cb = cb;

	if (!device_is_ready(dev)) {
		LOG_ERR("BMI270 not ready (init failed)");
		return -ENODEV;
	}
	if (bmi270_reg_read(dev, REG_CHIP_ID, &id, 1) != 0 || id != CHIP_ID) {
		LOG_ERR("BMI270 chip id 0x%02x", id);
		return -EIO;
	}
	if (!gpio_is_ready_dt(&int1)) {
		return -ENODEV;
	}

	gpio_pin_configure_dt(&int1, GPIO_INPUT);
	gpio_init_callback(&int1_cb, int1_isr, BIT(int1.pin));
	gpio_add_callback_dt(&int1, &int1_cb);

	present = true;
	LOG_INF("BMI270 ready");
	return 0;
}

int imu_start(const struct proto_rec_cfg *cfg)
{
	uint8_t odr = odr_bits(cfg->odr_hz);
	uint8_t id = 0;
	int err = 0;

	if (!present || atomic_get(&running)) {
		return -EBUSY;
	}

	memset(&st, 0, sizeof(st));
	st.odr_hz = cfg->odr_hz;
	st.nominal_ns = 1000000000u / cfg->odr_hz;
	st.period_ns = st.nominal_ns;
	/* A batch every ~100 ms. */
	st.wtm_frames = CLAMP(cfg->odr_hz / 10, 2, 100);
	atomic_set(&period_ns_shared, st.period_ns);

	/* Leave advanced power save first; writes need 450 us gaps until then. */
	k_usleep(500);
	err |= wr(REG_PWR_CONF, 0);
	k_usleep(500);

	err |= bmi270_reg_read(dev, REG_CHIP_ID, &id, 1);
	if (err || id != CHIP_ID) {
		LOG_ERR("BMI270 not responding (id 0x%02x)", id);
		power_down();
		return -EIO;
	}

	err |= wr(REG_INT_MAP_DATA, 0);
	err |= wr(REG_PWR_CTRL, 0);
	err |= wr(REG_FIFO_CONFIG_1, 0);
	err |= wr(REG_ACC_CONF, odr | ACC_CONF_BWP_NORM_AVG4 | ACC_CONF_FILTER_PERF);
	err |= wr(REG_ACC_RANGE, acc_range_bits(cfg->accel_range_g));
	err |= wr(REG_GYR_CONF, odr | GYR_CONF_BWP_NORM | GYR_CONF_NOISE_PERF | GYR_CONF_FILTER_PERF);
	err |= wr(REG_GYR_RANGE, gyr_range_bits(cfg->gyro_range_dps));
	err |= wr(REG_FIFO_DOWNS, FIFO_DOWNS_FILTERED);
	err |= wr(REG_FIFO_CONFIG_0, 0);
	err |= wr(REG_FIFO_CONFIG_1, FIFO_CONFIG_1_ACC_GYR);

	uint16_t wtm = st.wtm_frames * FRAME_BYTES;
	uint8_t wtm_b[2] = {wtm & 0xFF, (wtm >> 8) & 0x1F};

	err |= bmi270_reg_write(dev, REG_FIFO_WTM_0, wtm_b, 2);
	err |= wr(REG_INT1_IO_CTRL, INT_IO_OUTPUT_EN | INT_IO_ACTIVE_HIGH);
	err |= wr(REG_INT_LATCH, 0);
	err |= wr(REG_PWR_CTRL, PWR_CTRL_ACC | PWR_CTRL_GYR);

	k_msleep(MAX(STARTUP_MS, 3 * 1000 / cfg->odr_hz));

	uint8_t errreg = 0;

	err |= bmi270_reg_read(dev, REG_ERR, &errreg, 1);
	if (err || (errreg & BIT(0))) {
		LOG_ERR("BMI270 start failed (err %d, ERR_REG 0x%02x)", err, errreg);
		power_down();
		return -EIO;
	}

	/*
	 * Drop the start-up samples. The next frame is sample 0. The watermark
	 * interrupt isn't mapped yet, so no stale edge can be pending after this.
	 */
	err |= wr(REG_CMD, CMD_FIFO_FLUSH);

	k_spinlock_key_t key = k_spin_lock(&irq_lock);

	irq_pending = false;
	k_spin_unlock(&irq_lock, key);

	err |= gpio_pin_interrupt_configure_dt(&int1, GPIO_INT_EDGE_TO_ACTIVE);
	err |= wr(REG_INT_MAP_DATA, INT_MAP_FWM_INT1);
	if (err) {
		power_down();
		return -EIO;
	}

	atomic_set(&stop_req, 0);
	atomic_set(&running, 1);
	k_sem_give(&wake_sem);

	LOG_INF("started: %u Hz, %u g, %u dps, watermark %u frames", cfg->odr_hz,
		cfg->accel_range_g, cfg->gyro_range_dps, st.wtm_frames);
	return 0;
}

void imu_stop(void)
{
	if (!atomic_get(&running)) {
		return;
	}

	k_sem_reset(&stopped_sem);
	atomic_set(&stop_req, 1);
	k_sem_give(&wake_sem);
	k_sem_take(&stopped_sem, K_FOREVER);
	LOG_INF("stopped after %u samples", st.next_index);
}
```

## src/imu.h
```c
/*
 * BMI270 accelerometer + gyroscope, read through its FIFO.
 */
#ifndef BLADING_IMU_H_
#define BLADING_IMU_H_

#include <stdbool.h>
#include <stdint.h>

#include "proto.h"

/*
 * Called from the IMU thread for each FIFO read: n samples, the first with
 * sample index `index`, taken at t_us (tag clock). `lost` samples were lost
 * to a FIFO overflow just before this batch; `index` already skips them.
 */
typedef void (*imu_batch_cb_t)(const struct imu6 *s, uint32_t n, uint32_t index, uint64_t t_us,
			       uint32_t lost);

/* Probe the sensor. Returns 0 if it's usable. */
int imu_init(imu_batch_cb_t cb);

/*
 * Configure and start sampling. Blocks ~50 ms while the gyroscope starts up;
 * those start-up samples are discarded and sample 0 is the first valid one.
 */
int imu_start(const struct proto_rec_cfg *cfg);

/*
 * Stop sampling. Delivers the samples still in the FIFO through the callback
 * before it returns, then puts the sensor into suspend.
 */
void imu_stop(void);

/* Current estimate of the true sample period in ns (fitted to the tag clock). */
uint32_t imu_period_ns(void);

/* Tag clock: microseconds since boot (GRTC). */
uint64_t tag_time_us(void);

#endif /* BLADING_IMU_H_ */
```

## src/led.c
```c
#include <zephyr/drivers/gpio.h>
#include <zephyr/kernel.h>
#include <zephyr/sys/util.h>

#include "led.h"

static const struct gpio_dt_spec leds[] = {
	GPIO_DT_SPEC_GET(DT_NODELABEL(led1_red), gpios),
	GPIO_DT_SPEC_GET(DT_NODELABEL(led1_green), gpios),
	GPIO_DT_SPEC_GET(DT_NODELABEL(led1_blue), gpios),
};

#define BLIP_MS 30

static struct k_spinlock lock;
static enum led_mode mode;
static bool dropping;
static int64_t flash_until;
static uint8_t flash_colors;
static int64_t identify_until;

static void tick_fn(struct k_work *work);
static K_WORK_DELAYABLE_DEFINE(tick_work, tick_fn);

static void show(uint8_t colors)
{
	for (size_t i = 0; i < ARRAY_SIZE(leds); i++) {
		gpio_pin_set_dt(&leds[i], (colors >> i) & 1);
	}
}

static void tick_fn(struct k_work *work)
{
	int64_t now = k_uptime_get();
	uint8_t colors = 0;
	int64_t next = -1;
	k_spinlock_key_t key = k_spin_lock(&lock);

	if (now < flash_until) {
		colors = flash_colors;
		next = flash_until - now;
	} else if (now < identify_until) {
		int64_t ph = now % 500;

		colors = ph < 250 ? LED_BLUE : 0;
		next = (ph < 250 ? 250 : 500) - ph;
	} else if (mode != LED_MODE_OFF) {
		int64_t period = mode == LED_MODE_RECORDING ? 2000 : 1000;
		int64_t ph = now % period;

		if (ph < BLIP_MS) {
			colors = mode == LED_MODE_RECORDING ? LED_GREEN
				 : dropping		     ? LED_RED
							     : LED_YELLOW;
			next = BLIP_MS - ph;
		} else {
			next = period - ph;
		}
	}
	k_spin_unlock(&lock, key);

	show(colors);
	if (next >= 0) {
		k_work_reschedule(&tick_work, K_MSEC(MAX(next, 1)));
	}
}

void led_init(void)
{
	for (size_t i = 0; i < ARRAY_SIZE(leds); i++) {
		gpio_pin_configure_dt(&leds[i], GPIO_OUTPUT_INACTIVE);
	}
}

void led_set_mode(enum led_mode m)
{
	k_spinlock_key_t key = k_spin_lock(&lock);

	mode = m;
	k_spin_unlock(&lock, key);
	k_work_reschedule(&tick_work, K_NO_WAIT);
}

void led_set_dropping(bool d)
{
	k_spinlock_key_t key = k_spin_lock(&lock);
	bool changed = dropping != d;

	dropping = d;
	k_spin_unlock(&lock, key);
	if (changed) {
		k_work_reschedule(&tick_work, K_NO_WAIT);
	}
}

void led_flash(uint8_t colors, uint16_t ms)
{
	k_spinlock_key_t key = k_spin_lock(&lock);

	flash_colors = colors;
	flash_until = k_uptime_get() + ms;
	k_spin_unlock(&lock, key);
	k_work_reschedule(&tick_work, K_NO_WAIT);
}

void led_identify(uint8_t seconds)
{
	k_spinlock_key_t key = k_spin_lock(&lock);

	identify_until = seconds ? k_uptime_get() + seconds * 1000 : 0;
	k_spin_unlock(&lock, key);
	k_work_reschedule(&tick_work, K_NO_WAIT);
}
```

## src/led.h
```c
/*
 * RGB status LED. Patterns are short blips to keep the average current low.
 */
#ifndef BLADING_LED_H_
#define BLADING_LED_H_

#include <stdbool.h>
#include <stdint.h>
#include <zephyr/sys/util.h>

#define LED_RED    BIT(0)
#define LED_GREEN  BIT(1)
#define LED_BLUE   BIT(2)
#define LED_YELLOW (LED_RED | LED_GREEN)

enum led_mode {
	LED_MODE_OFF,
	/* Recording and connected: green blip every 2 s. */
	LED_MODE_RECORDING,
	/*
	 * Recording into the buffer, no link: yellow blip every second. Red
	 * instead once the buffer is full and samples are being dropped
	 * (led_set_dropping), i.e. the phone never joined or lost the tag.
	 */
	LED_MODE_BUFFERING,
};

void led_init(void);
void led_set_mode(enum led_mode mode);
/* Samples are being dropped: LED_MODE_BUFFERING blips red. Cheap to call often. */
void led_set_dropping(bool dropping);
/* Light `colors` for ms, then go back to the mode pattern. */
void led_flash(uint8_t colors, uint16_t ms);
/* Blink blue for seconds (0 stops). */
void led_identify(uint8_t seconds);

#endif /* BLADING_LED_H_ */
```

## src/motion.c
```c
/*
 * ADXL367 wake-on-motion.
 *
 * The ADXL367 runs in wake-up mode (~6 Hz, ~0.2 uA) with referenced activity
 * detection on INT1 (P0.03, from the locator_tag sample's board overlay). It
 * does two jobs:
 * - In READY, its interrupt marks "the skate moved", for the idle timeout.
 * - In System OFF, INT1 is a GPIO SENSE wake-up source.
 *
 * Zephyr's ADXL367 driver is disabled. Its activity mode doesn't do wake-up
 * mode, and the locator_tag sample notes its activity detection is unreliable,
 * so the few registers needed are written directly.
 */
#include "motion.h"

#include <hal/nrf_gpio.h>
#include <zephyr/drivers/gpio.h>
#include <zephyr/drivers/i2c.h>
#include <zephyr/kernel.h>
#include <zephyr/logging/log.h>

LOG_MODULE_REGISTER(motion, LOG_LEVEL_INF);

#define REG_DEVID_AD      0x00
#define REG_PARTID        0x02
#define REG_STATUS        0x0B
#define REG_SOFT_RESET    0x1F
#define REG_THRESH_ACT_H  0x20
#define REG_THRESH_ACT_L  0x21
#define REG_TIME_ACT      0x22
#define REG_ACT_INACT_CTL 0x27
#define REG_INTMAP1_LOWER 0x2A
#define REG_FILTER_CTL    0x2C
#define REG_POWER_CTL     0x2D

#define DEVID_AD_VAL     0xAD
#define PARTID_VAL       0xF7
#define RESET_CODE       0x52
#define ACT_EN           BIT(0)
#define ACT_REF          BIT(1)
#define INTMAP_ACT       BIT(4)
#define POWER_CTL_MEASURE 0x02
#define POWER_CTL_WAKEUP BIT(3)
#define STATUS_ACT       BIT(4)

/* +-2 g range: 0.25 mg per LSB. */
#define THRESH_LSB (CONFIG_BLADING_MOTION_THRESHOLD_MG * 4)

static const struct i2c_dt_spec i2c = I2C_DT_SPEC_GET(DT_NODELABEL(adxl367));
static const struct gpio_dt_spec int1 = GPIO_DT_SPEC_GET(DT_NODELABEL(adxl367), int1_gpios);
static struct gpio_callback int1_cb;

#define INT1_NRF_PIN                                                                               \
	NRF_GPIO_PIN_MAP(DT_PROP(DT_GPIO_CTLR(DT_NODELABEL(adxl367), int1_gpios), port),          \
			 DT_GPIO_PIN(DT_NODELABEL(adxl367), int1_gpios))

static bool present;
static bool wake_armed;
static atomic_t last_motion_s;
static atomic_t isr_count;

static void rearm_fn(struct k_work *work);
static K_WORK_DELAYABLE_DEFINE(rearm_work, rearm_fn);

static int wr(uint8_t reg, uint8_t val)
{
	return i2c_reg_write_byte_dt(&i2c, reg, val);
}

/*
 * Re-enable referenced activity detection, which takes a new reference
 * (the current orientation), and clear the latched interrupt.
 */
static int arm(void)
{
	uint8_t status;
	int err = 0;

	err |= wr(REG_ACT_INACT_CTL, 0);
	err |= wr(REG_ACT_INACT_CTL, ACT_EN | ACT_REF);
	err |= i2c_reg_read_byte_dt(&i2c, REG_STATUS, &status);
	return err;
}

static void rearm_fn(struct k_work *work)
{
	arm();
}

static void int1_isr(const struct device *port, struct gpio_callback *cb, uint32_t pins)
{
	atomic_set(&last_motion_s, (atomic_val_t)k_uptime_seconds());
	atomic_inc(&isr_count);
	/* Rate-limit: re-arm (and so allow the next interrupt) a second later. */
	k_work_reschedule(&rearm_work, K_SECONDS(1));
}

int motion_init(void)
{
	uint8_t id[3];
	int err;

	atomic_set(&last_motion_s, (atomic_val_t)k_uptime_seconds());

	if (!i2c_is_ready_dt(&i2c) || !gpio_is_ready_dt(&int1)) {
		return -ENODEV;
	}

	err = wr(REG_SOFT_RESET, RESET_CODE);
	k_msleep(10);
	err |= i2c_burst_read_dt(&i2c, REG_DEVID_AD, id, sizeof(id));
	if (err || id[0] != DEVID_AD_VAL || id[2] != PARTID_VAL) {
		LOG_ERR("ADXL367 not found (err %d, id %02x/%02x)", err, id[0], id[2]);
		return -EIO;
	}

	/* Configure in standby, then start measuring in wake-up mode. */
	err |= wr(REG_FILTER_CTL, 0x00); /* +-2 g */
	err |= wr(REG_THRESH_ACT_H, (THRESH_LSB >> 6) & 0x7F);
	err |= wr(REG_THRESH_ACT_L, (THRESH_LSB & 0x3F) << 2);
	err |= wr(REG_TIME_ACT, 1);
	err |= wr(REG_INTMAP1_LOWER, INTMAP_ACT); /* active high */
	err |= wr(REG_POWER_CTL, POWER_CTL_WAKEUP | POWER_CTL_MEASURE);
	k_msleep(20);
	err |= arm();
	if (err) {
		LOG_ERR("ADXL367 setup failed");
		return -EIO;
	}

	gpio_pin_configure_dt(&int1, GPIO_INPUT);
	gpio_init_callback(&int1_cb, int1_isr, BIT(int1.pin));
	gpio_add_callback_dt(&int1, &int1_cb);
	gpio_pin_interrupt_configure_dt(&int1, GPIO_INT_EDGE_TO_ACTIVE);

	present = true;
	LOG_INF("ADXL367 wake-on-motion armed (%d mg)", CONFIG_BLADING_MOTION_THRESHOLD_MG);
	return 0;
}

bool motion_available(void)
{
	return present;
}

uint32_t motion_last_s(void)
{
	return (uint32_t)atomic_get(&last_motion_s);
}

int motion_prepare_sysoff(void)
{
	uint8_t status = 0;

	if (!present) {
		return -ENODEV;
	}

	k_work_cancel_delayable(&rearm_work);
	gpio_pin_interrupt_configure_dt(&int1, GPIO_INT_DISABLE);

	/* Reference the resting orientation; wake-up mode samples at ~6 Hz. */
	arm();
	k_msleep(400);
	arm();
	k_msleep(400);

	i2c_reg_read_byte_dt(&i2c, REG_STATUS, &status);
	int level = gpio_pin_get_dt(&int1);

	LOG_INF("sleep: ADXL367 STATUS 0x%02x, INT1 %d, %u interrupts since boot", status, level,
		(unsigned int)atomic_get(&isr_count));
	if (level != 0) {
		/* Would wake us right away (or keep waking us): button only. */
		LOG_WRN("INT1 still active, not using motion wake-up");
		return -EBUSY;
	}
	wake_armed = true;
	return 0;
}

void motion_arm_wake(void)
{
	if (wake_armed) {
		nrf_gpio_cfg_sense_set(INT1_NRF_PIN, NRF_GPIO_PIN_SENSE_HIGH);
	}
}

void motion_cancel_sysoff(void)
{
	wake_armed = false;
	if (!present) {
		return;
	}
	arm();
	gpio_pin_interrupt_configure_dt(&int1, GPIO_INT_EDGE_TO_ACTIVE);
}

uint32_t motion_int1_pin(void)
{
	return INT1_NRF_PIN;
}
```
